# STM32C542xx register map
File version: 1.0
Registers are 32-bit, read-write, reset 0x0 unless marked. A register's access mark holds for its fields unless they carry their own. Offsets are from the block's base; [hi:lo] are bit positions; {n}, {i} and the like mark numbered series; 'fields as' and 'values as' point back to an identical list.

## FLASH — FLASH Registers
Base 0x40022000
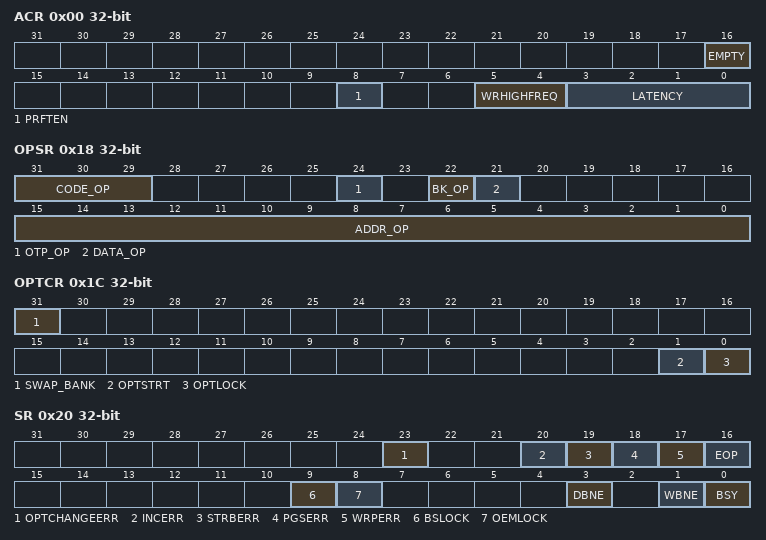
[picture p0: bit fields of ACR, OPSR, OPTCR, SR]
0x00 ACR — FLASH access control register
  [16] EMPTY
  [8] PRFTEN — Prefetch enable
  [5:4] WRHIGHFREQ — FLASH signal delay
  [3:0] LATENCY — Read latency
0x04 KEYR — FLASH key register
  [31:0] KEY
0x0C OPTKEYR — FLASH option key register
  [31:0] OPTKEY
0x18 OPSR ro — FLASH operation status register
  [31:29] CODE_OP, [24] OTP_OP, [22] BK_OP, [21] DATA_OP, [15:0] ADDR_OP
0x1C OPTCR — FLASH option control register
  [31] SWAP_BANK, [1] OPTSTRT, [0] OPTLOCK
0x20 SR ro — FLASH status register
  [23] OPTCHANGEERR
  [20] INCERR
  [19] STRBERR — strobe error flag
  [18] PGSERR
  [17] WRPERR
  [16] EOP
  [9] BSLOCK
  [8] OEMLOCK
  [3] DBNE
  [1] WBNE
  [0] BSY — busy flag
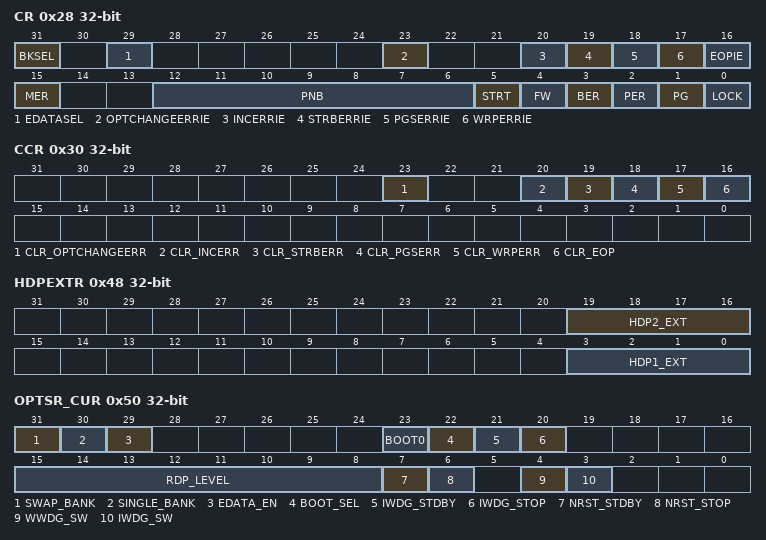
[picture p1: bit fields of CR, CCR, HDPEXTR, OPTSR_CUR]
0x28 CR — FLASH control register
  [31] BKSEL — Bank selector bit
  [29] EDATASEL
  [23] OPTCHANGEERRIE
  [20] INCERRIE
  [19] STRBERRIE
  [18] PGSERRIE
  [17] WRPERRIE
  [16] EOPIE
  [15] MER — Mass erase request
  [12:6] PNB
  [5] STRT
  [4] FW
  [3] BER — Bank erase request
  [2] PER — page erase request
  [1] PG
  [0] LOCK
0x30 CCR — FLASH clear control register
  [23] CLR_OPTCHANGEERR
  [20] CLR_INCERR
  [19] CLR_STRBERR
  [18] CLR_PGSERR
  [17] CLR_WRPERR
  [16] CLR_EOP — EOP flag clear bit
0x3C PRIVCFGR — FLASH privilege configuration register
  [1] PRIV — privilege attribute
0x48 HDPEXTR — FLASH HDP extension register
  [19:16] HDP2_EXT, [3:0] HDP1_EXT
0x50 OPTSR_CUR ro — FLASH option status register
  [31] SWAP_BANK
  [30] SINGLE_BANK
  [29] EDATA_EN
  [23] BOOT0 — Boot 0 option bit
  [22] BOOT_SEL
  [21] IWDG_STDBY
  [20] IWDG_STOP
  [15:8] RDP_LEVEL
  [7] NRST_STDBY
  [6] NRST_STOP
  [4] WWDG_SW
  [3] IWDG_SW
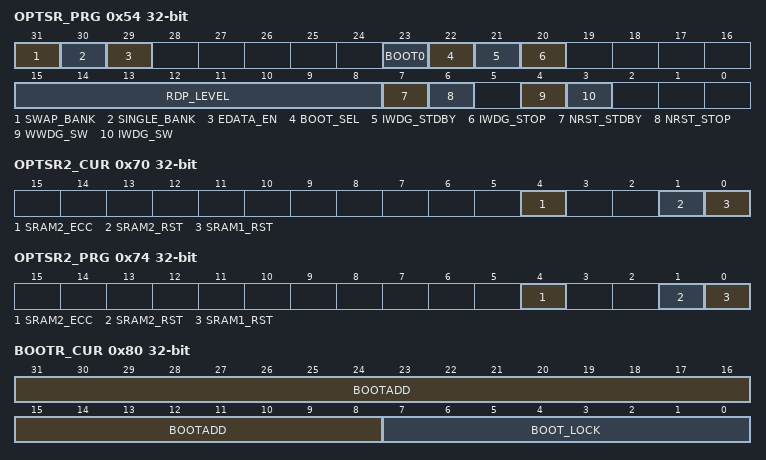
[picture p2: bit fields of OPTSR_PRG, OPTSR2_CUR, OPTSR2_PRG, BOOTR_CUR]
0x54 OPTSR_PRG — FLASH option status register
  fields as OPTSR_CUR
0x70 OPTSR2_CUR ro — FLASH option status register 2
  [4] SRAM2_ECC, [1] SRAM2_RST, [0] SRAM1_RST
0x74 OPTSR2_PRG — FLASH option status register 2
  [4] SRAM2_ECC, [1] SRAM2_RST, [0] SRAM1_RST
0x80 BOOTR_CUR ro — FLASH unique boot entry register
  [31:8] BOOTADD, [7:0] BOOT_LOCK
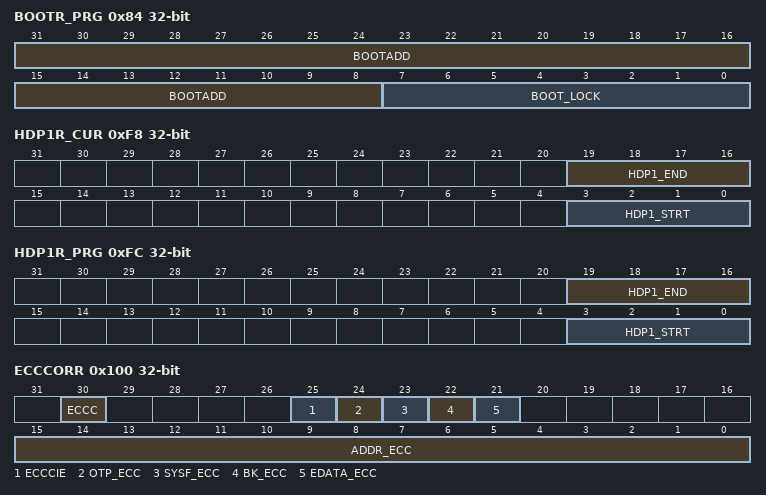
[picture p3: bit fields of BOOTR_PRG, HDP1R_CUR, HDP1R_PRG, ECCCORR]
0x84 BOOTR_PRG — FLASH unique boot entry address
  [31:8] BOOTADD, [7:0] BOOT_LOCK
0x90 OTPBLR_CUR ro — FLASH OTP block lock
  [23:0] LOCKBL — OTP block lock
0x94 OTPBLR_PRG — FLASH OTP block lock
  [23:0] LOCKBL — OTP block lock
0x98 BL_COM_CFG_CUR ro — FLASH Bootloader interface selection
  [31:0] BL_COM_CFG
0x9C BL_COM_CFG_PRG — FLASH Bootloader interface selection
  [31:0] BL_COM_CFG
{0x9C+8i} OEMKEYR{i}_PRG (i=1..4) — FLASH OEM Key register {i}
  [31:0] OEMKEY
0xC4 BSKEYR_PRG — FLASH Boundary Scan key register
  [31:0] BSKEY — Boundary Scan KEY
0xE8 WRP1R_CUR ro — FLASH write page protection for bank1
  [15:0] WRPSG1
0xEC WRP1R_PRG — FLASH write page protection for bank1
  [15:0] WRPSG1
0xF8 HDP1R_CUR ro — FLASH HDP bank1 register
  [19:16] HDP1_END, [3:0] HDP1_STRT
0xFC HDP1R_PRG — FLASH HDP bank1 register
  [19:16] HDP1_END, [3:0] HDP1_STRT
0x100 ECCCORR — FLASH ECC correction register
  [30] ECCC — ECC correction
  [25] ECCCIE
  [24] OTP_ECC — OTP ECC error bit
  [23] SYSF_ECC
  [22] BK_ECC
  [21] EDATA_ECC
  [15:0] ADDR_ECC — ECC error address
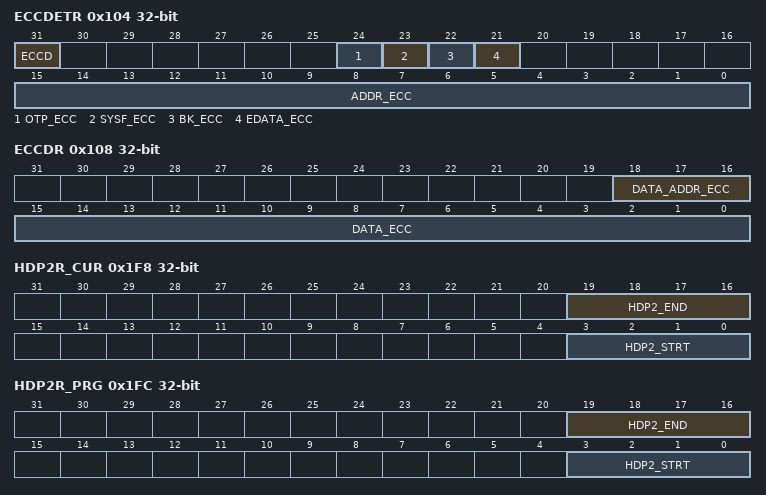
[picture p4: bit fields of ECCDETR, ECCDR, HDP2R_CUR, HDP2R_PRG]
0x104 ECCDETR — FLASH ECC detection register
  [31] ECCD
  [24] OTP_ECC — OTP ECC error bit
  [23] SYSF_ECC
  [22] BK_ECC
  [21] EDATA_ECC
  [15:0] ADDR_ECC — ECC error address
0x108 ECCDR ro — FLASH ECC data
  [18:16] DATA_ADDR_ECC
  [15:0] DATA_ECC — ECC error data
0x1E8 WRP2R_CUR ro — FLASH write page protection for bank2
  [15:0] WRPSG2
0x1EC WRP2R_PRG — FLASH write page protection for bank2
  [15:0] WRPSG2
0x1F8 HDP2R_CUR ro — FLASH HDP bank2 register
  [19:16] HDP2_END, [3:0] HDP2_STRT
0x1FC HDP2R_PRG — FLASH HDP bank2 register
  [19:16] HDP2_END, [3:0] HDP2_STRT

## CRC — CRC calculation unit
Base 0x40023000
0x00 DR — CRC Data register
  [31:0] DR — Data register bits
0x04 IDR — CRC Independent data register
  [31:0] IDR — General-purpose 32-bits data register bits
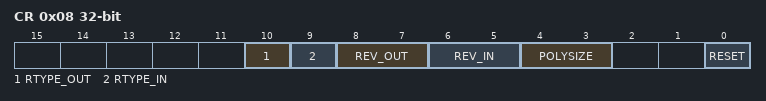
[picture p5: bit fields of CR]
0x08 CR — CRC Control register
  [10] RTYPE_OUT — Reverse type output
  [9] RTYPE_IN — Reverse type input
  [8:7] REV_OUT — REV_OUT Reverse Output Data bits
  [6:5] REV_IN — REV_IN Reverse Input Data bits
  [4:3] POLYSIZE — Polynomial size bits
  [0] RESET — RESET the CRC computation unit bit
0x10 INIT — Initial CRC value register
  [31:0] INIT — Initial CRC value bits
0x14 POL — CRC polynomial register
  [31:0] POL — Coefficients of the polynomial
